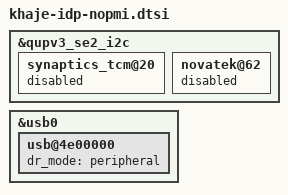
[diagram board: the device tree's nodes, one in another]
#include "khaje-idp.dtsi"

&qupv3_se2_i2c {
	synaptics_tcm@20 {
		status = "disabled";
	};

	novatek@62 {
		status = "disabled";
	};
};

&usb0 {
	/delete-property/ extcon;
	usb@4e00000 {
		dr_mode = "peripheral";
	};
};
